# STM32U5A5xx register map
File version: 1.0
Registers are 32-bit, read-write, reset 0x0 unless marked. A register's access mark holds for its fields unless they carry their own. Offsets are from the block's base; [hi:lo] are bit positions; {n}, {i} and the like mark numbered series.

## HASH
Base 0x420C0400
Same registers: HASH_S 0x520C0400
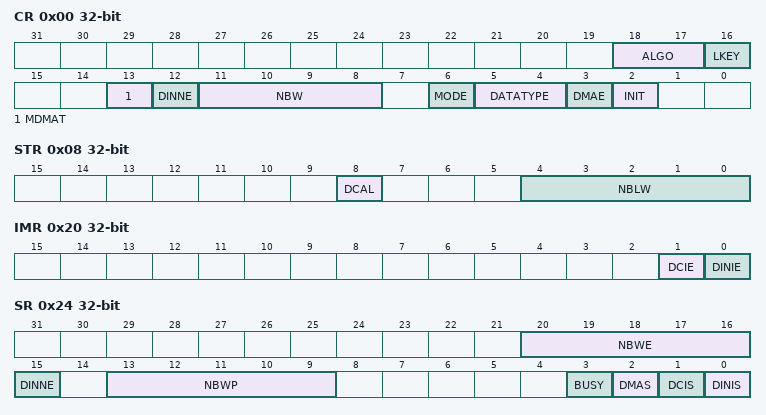
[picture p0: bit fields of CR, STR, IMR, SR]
0x00 CR — HASH control register
  [18:17] ALGO, [16] LKEY, [13] MDMAT, [12] DINNE, [11:8] NBW, [6] MODE, [5:4] DATATYPE, [3] DMAE, [2] INIT
0x04 DIN — HASH data input register
0x08 STR — HASH start register
  [8] DCAL, [4:0] NBLW
{0xC+4i} HR{i} (i=0..4) — HASH digest registers
0x20 IMR — HASH interrupt enable register
  [1] DCIE, [0] DINIE
0x24 SR — HASH status register
  [20:16] NBWE, [15] DINNE, [13:9] NBWP, [3] BUSY, [2] DMAS, [1] DCIS, [0] DINIS
{0xF8+4i} CSR{i} (i=0..53) — HASH context swap registers
{0x310+4i} DIGEST_HR{i} (i=0..7) — HASH digest registers

## RNG
Base 0x420C0800
Same registers: RNG_S 0x520C0800
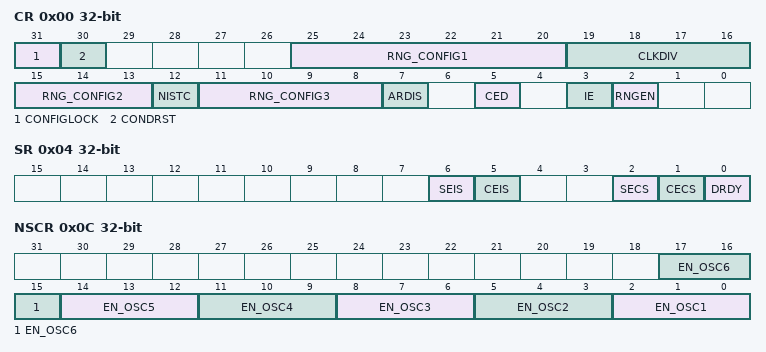
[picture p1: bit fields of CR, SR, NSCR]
0x00 CR — RNG control register
  [31] CONFIGLOCK
  [30] CONDRST
  [25:20] RNG_CONFIG1
  [19:16] CLKDIV
    0=BY_1 (No clock division); 1=BY_2 (2 RNG clock cycles per internal RNG clock); 2=BY_4 (4 RNG clock cycles per internal RNG clock); 3=BY_8 (8 RNG clock cycles per internal RNG clock); 4=BY_16 (16 RNG clock cycles per internal RNG clock); 5=BY_32 (32 RNG clock cycles per internal RNG clock); 6=BY_64 (64 RNG clock cycles per internal RNG clock); 7=BY_128 (128 RNG clock cycles per internal RNG clock); 8=BY_256 (256 RNG clock cycles per internal RNG clock); 9=BY_512 (512 RNG clock cycles per internal RNG clock); 10=BY_1024 (1024 RNG clock cycles per internal RNG clock); 11=BY_2048 (2048 RNG clock cycles per internal RNG clock); 12=BY_4096 (4096 RNG clock cycles per internal RNG clock); 13=BY_8192 (8192 RNG clock cycles per internal RNG clock); 14=BY_16384 (16384 RNG clock cycles per internal RNG clock); 15=BY_32768 (32768 RNG clock cycles per internal RNG clock)
  [15:13] RNG_CONFIG2
  [12] NISTC
  [11:8] RNG_CONFIG3
  [7] ARDIS
  [5] CED
  [3] IE
  [2] RNGEN
0x04 SR — RNG status register
  [6] SEIS, [5] CEIS, [2] SECS, [1] CECS, [0] DRDY
0x08 DR — RNG data register
0x0C NSCR — RNG noise source control register
  [3n-1:3n-3] EN_OSC{n} (n=1..6)
0x10 HTCR — RNG health test configuration register
  [31:0] HTCFG

## PKA
Base 0x420C2000
Same registers: PKA_S 0x520C2000
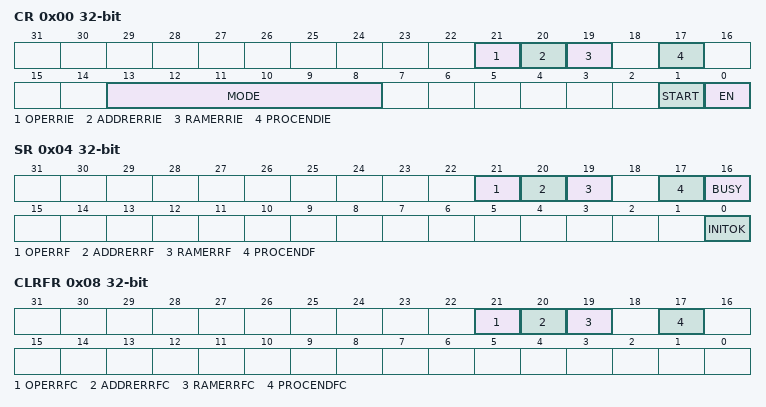
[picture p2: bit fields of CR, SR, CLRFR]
0x00 CR — PKA control register
  [21] OPERRIE — Operation Error interrupt enable
  [20] ADDRERRIE — Address error interrupt enable
  [19] RAMERRIE — RAM error interrupt enable
  [17] PROCENDIE — End of operation interrupt enable
  [13:8] MODE — MODE[5:0] PKA operation code
  [1] START — Start operation
  [0] EN — PKA enable
0x04 SR — PKA status register
  [21] OPERRF — PKA operation Error flag
  [20] ADDRERRF — Address error flag
  [19] RAMERRF — PKA RAM error flag
  [17] PROCENDF — PKA end of operation flag
  [16] BUSY — PKA operation is in progress
  [0] INITOK — PKA initialisation flag
0x08 CLRFR — PKA clear flag register
  [21] OPERRFC — Clear PKA operation Error flag
  [20] ADDRERRFC — Clear address error flag
  [19] RAMERRFC — Clear PKA RAM error flag
  [17] PROCENDFC — Clear PKA end of operation flag
{0x400+4i} RAM[{i}] (i=0..1333)

## OCTOSPIM — Serial Peripheral Interface IO Manager
Base 0x420C4000
Same registers: OCTOSPIM_S 0x520C4000
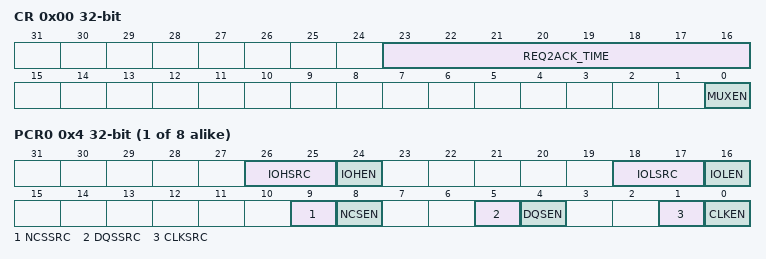
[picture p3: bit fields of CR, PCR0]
0x00 CR — OCTOSPIM IO Manager Control register
  [23:16] REQ2ACK_TIME — REQ to ACK Time
  [0] MUXEN — Multiplexed Mode Enable
{0x4+4i} PCR{i} (i=0..7) — OCTOSPIM IO Manager Port[1:8] Configuration register
  [26:25] IOHSRC — IO[7:4] Source for Port n
  [24] IOHEN — IO[7:4] Enable for Port n
  [18:17] IOLSRC — IO[3:0] Source for Port n
  [16] IOLEN — IO[3:0] Enable for Port n
  [9] NCSSRC — nCS Source for Port n
  [8] NCSEN — nCS Enable for Port n
  [5] DQSSRC — DQS Source for Port n
  [4] DQSEN — DQS Enable for Port n
  [1] CLKSRC — CLK/CLKn Source for Port n
  [0] CLKEN — CLK/CLKn Enable for Port n

## DLYB_SDMMC1 — Delay Block DLYB
Base 0x420C8400
Same registers: DLYB_SDMMC2 0x420C8800, DLYB_OCTOSPI1 0x420CF000, DLYB_OCTOSPI2 0x420CF400, DLYB_SDMMC1_S 0x520C8400, DLYB_SDMMC2_S 0x520C8800, DLYB_OCTOSPI1_S 0x520CF000, DLYB_OCTOSPI2_S 0x520CF400
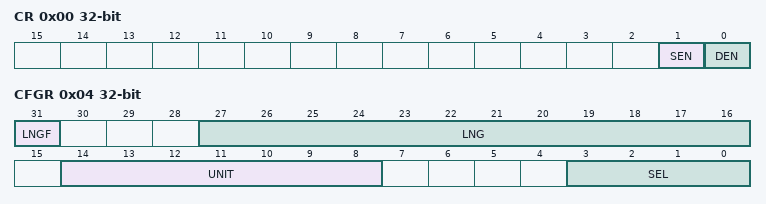
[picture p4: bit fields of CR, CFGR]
0x00 CR — DELAY BLOCK control register
  [1] SEN — Sampler length enable
  [0] DEN — Delay Block enable
0x04 CFGR — DELAY BLOCK configuration register
  [31] LNGF — Length valid flag
  [27:16] LNG — Delay line length value[11:0]
  [14:8] UNIT — Delay Defines the delay of a Unit delay cell[6:0]
  [3:0] SEL — Select the phase for the Output clock[3:0]
